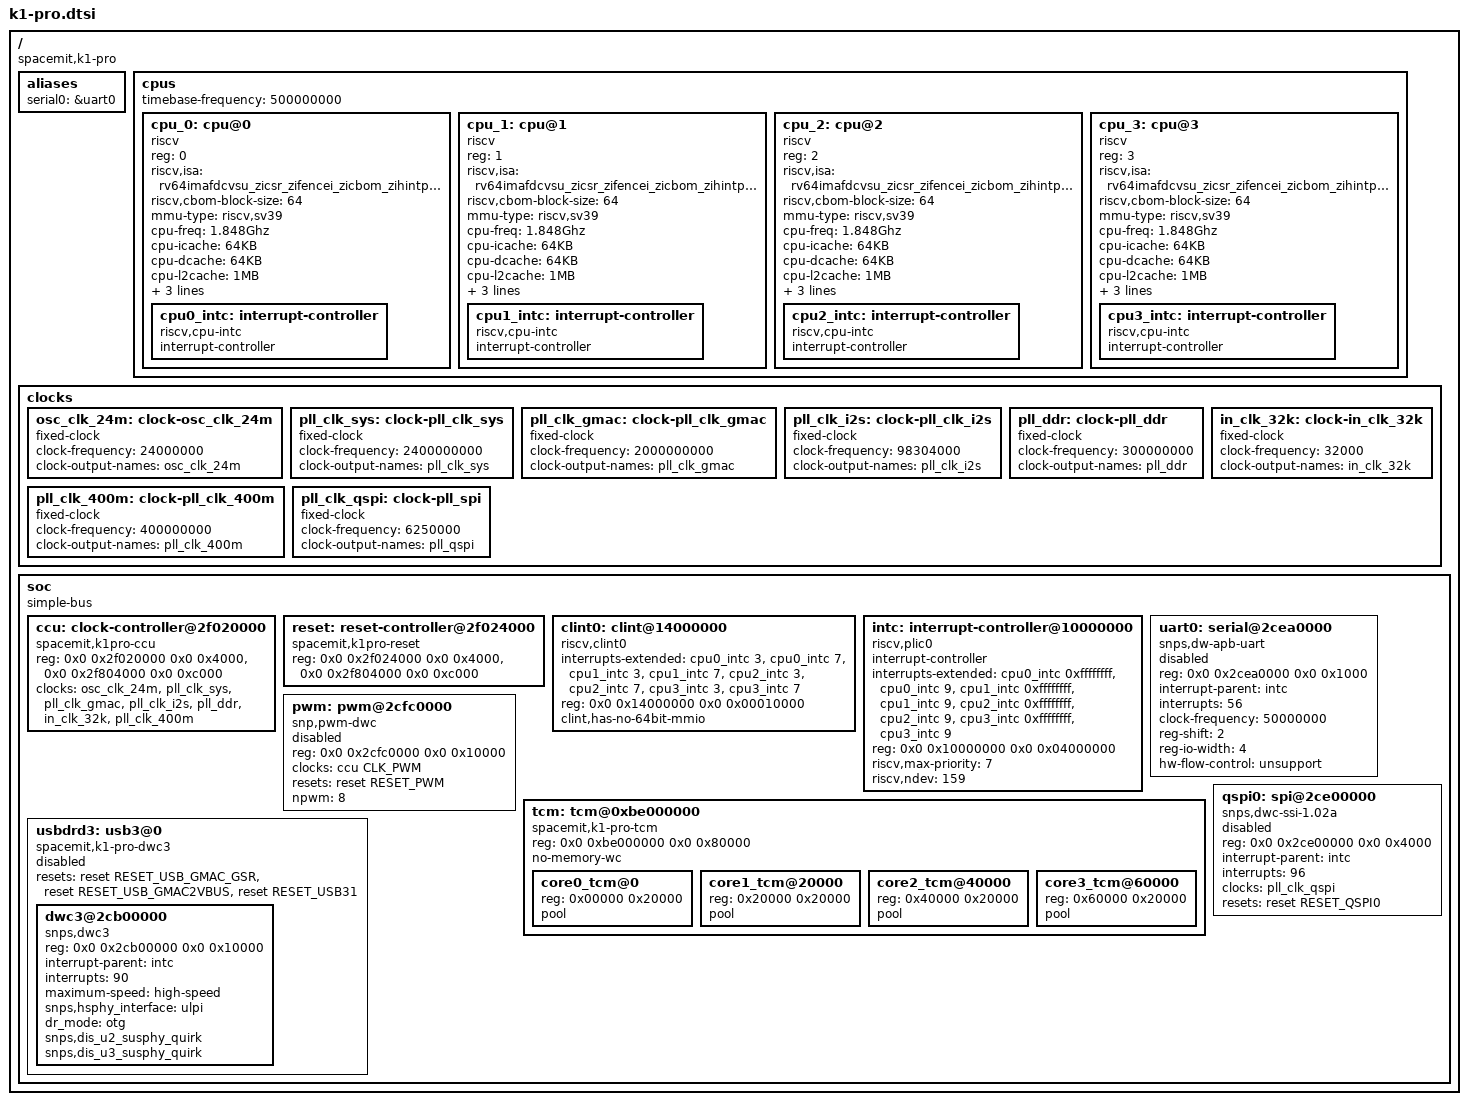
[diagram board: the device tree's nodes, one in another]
// SPDX-License-Identifier: (GPL-2.0 OR MIT)
/* Copyright (c) 2022 Spacemit, Inc */

/dts-v1/;

/dts-v1/;

#include <dt-bindings/clock/k1-pro-ccu-clock.h>
#include <dt-bindings/reset/k1-pro-reset.h>

/ {
	compatible = "spacemit,k1-pro", "riscv";
	#address-cells = <2>;
	#size-cells = <2>;

	aliases {
		serial0 = &uart0;
	};

	cpus: cpus {
		#address-cells = <1>;
		#size-cells = <0>;
		timebase-frequency = <500000000>;
		cpu_0: cpu@0 {
			device_type = "cpu";
			reg = <0>;
			status = "okay";
			compatible = "riscv";
			riscv,isa = "rv64imafdcvsu_zicsr_zifencei_zicbom_zihintpause_zba_zbb_zbc_zbs_svpbmt";
			riscv,cbom-block-size = <64>;
			mmu-type = "riscv,sv39";
			cpu-freq = "1.848Ghz";
			cpu-icache = "64KB";
			cpu-dcache = "64KB";
			cpu-l2cache = "1MB";
			cpu-tlb = "1024 4-ways";
			cpu-cacheline = "64Bytes";
			cpu-vector = "0.7.1";

			cpu0_intc: interrupt-controller {
				#interrupt-cells = <1>;
				compatible = "riscv,cpu-intc";
				interrupt-controller;
			};
		};
		cpu_1: cpu@1 {
			device_type = "cpu";
			reg = <1>;
			status = "okay";
			compatible = "riscv";
			riscv,isa = "rv64imafdcvsu_zicsr_zifencei_zicbom_zihintpause_zba_zbb_zbc_zbs_svpbmt";
			riscv,cbom-block-size = <64>;
			mmu-type = "riscv,sv39";
			cpu-freq = "1.848Ghz";
			cpu-icache = "64KB";
			cpu-dcache = "64KB";
			cpu-l2cache = "1MB";
			cpu-tlb = "1024 4-ways";
			cpu-cacheline = "64Bytes";
			cpu-vector = "0.7.1";

			cpu1_intc: interrupt-controller {
				#interrupt-cells = <1>;
				compatible = "riscv,cpu-intc";
				interrupt-controller;
			};
		};
		cpu_2: cpu@2 {
			device_type = "cpu";
			reg = <2>;
			status = "okay";
			compatible = "riscv";
			riscv,isa = "rv64imafdcvsu_zicsr_zifencei_zicbom_zihintpause_zba_zbb_zbc_zbs_svpbmt";
			riscv,cbom-block-size = <64>;
			mmu-type = "riscv,sv39";
			cpu-freq = "1.848Ghz";
			cpu-icache = "64KB";
			cpu-dcache = "64KB";
			cpu-l2cache = "1MB";
			cpu-tlb = "1024 4-ways";
			cpu-cacheline = "64Bytes";
			cpu-vector = "0.7.1";

			cpu2_intc: interrupt-controller {
				#interrupt-cells = <1>;
				compatible = "riscv,cpu-intc";
				interrupt-controller;
			};
		};
		cpu_3: cpu@3 {
			device_type = "cpu";
			reg = <3>;
			status = "okay";
			compatible = "riscv";
			riscv,isa = "rv64imafdcvsu_zicsr_zifencei_zicbom_zihintpause_zba_zbb_zbc_zbs_svpbmt";
			riscv,cbom-block-size = <64>;
			mmu-type = "riscv,sv39";
			cpu-freq = "1.848Ghz";
			cpu-icache = "64KB";
			cpu-dcache = "64KB";
			cpu-l2cache = "1MB";
			cpu-tlb = "1024 4-ways";
			cpu-cacheline = "64Bytes";
			cpu-vector = "0.7.1";

			cpu3_intc: interrupt-controller {
				#interrupt-cells = <1>;
				compatible = "riscv,cpu-intc";
				interrupt-controller;
			};
		};
	};

	clocks {
		#address-cells = <0x2>;
		#size-cells = <0x2>;
		ranges;

		osc_clk_24m: clock-osc_clk_24m {
			#clock-cells = <0>;
			compatible = "fixed-clock";
			clock-frequency = <24000000>;
			clock-output-names = "osc_clk_24m";
		};

		pll_clk_sys: clock-pll_clk_sys {
			#clock-cells = <0>;
			compatible = "fixed-clock";
			clock-frequency = <2400000000>;
			clock-output-names = "pll_clk_sys";
			};

		pll_clk_gmac: clock-pll_clk_gmac {
			#clock-cells = <0>;
			compatible = "fixed-clock";
			clock-frequency = <2000000000>;
			clock-output-names = "pll_clk_gmac";
		};
		pll_clk_i2s: clock-pll_clk_i2s {
			#clock-cells = <0>;
			compatible = "fixed-clock";
			clock-frequency = <98304000>;
			clock-output-names = "pll_clk_i2s";
		};

		pll_ddr: clock-pll_ddr {
			#clock-cells = <0>;
			compatible = "fixed-clock";
			clock-frequency = <300000000>;
			clock-output-names = "pll_ddr";
		};

		in_clk_32k: clock-in_clk_32k {
			#clock-cells = <0>;
			compatible = "fixed-clock";
			clock-frequency = <32000>;
			clock-output-names = "in_clk_32k";
		};

		pll_clk_400m: clock-pll_clk_400m {
			#clock-cells = <0>;
			compatible = "fixed-clock";
			clock-frequency = <400000000>;
			clock-output-names = "pll_clk_400m";
		};

               pll_clk_qspi: clock-pll_spi {
		       #clock-cells = <0>;
                       compatible = "fixed-clock";
                       clock-frequency = <6250000>;
                       clock-output-names = "pll_qspi";
               };
	};
	soc {
		compatible = "simple-bus";
		#address-cells = <2>;
		#size-cells = <2>;
		ranges;
		ccu:clock-controller@2f020000 {
		    #address-cells = <0x1>;
		    #size-cells = <0x1>;
			compatible = "spacemit,k1pro-ccu";
			reg = <0x0 0x2f020000 0x0 0x4000>, <0x0 0x2f804000 0x0 0xc000>;
			clocks = <&osc_clk_24m>, <&pll_clk_sys>, <&pll_clk_gmac>, <&pll_clk_i2s>, <&pll_ddr>, <&in_clk_32k>, <&pll_clk_400m>;
			clock-names = "osc_clk_24m", "pll_clk_sys", "pll_clk_gmac", "pll_clk_i2s", "pll_ddr", "in_clk_32k", "pll_clk_400m";
			#clock-cells = <1>;
			status = "okay";
		};

		reset: reset-controller@2f024000 {
		    #address-cells = <0x1>;
		    #size-cells = <0x1>;
			compatible = "spacemit,k1pro-reset";
			reg = <0x0 0x2f024000 0x0 0x4000>, <0x0 0x2f804000 0x0 0xc000>;
			#reset-cells = <1>;
			status = "okay";
		};

		clint0: clint@14000000 {
			compatible = "riscv,clint0";
			interrupts-extended = <
				&cpu0_intc  3 &cpu0_intc  7
				&cpu1_intc  3 &cpu1_intc  7
				&cpu2_intc  3 &cpu2_intc  7
				&cpu3_intc  3 &cpu3_intc  7
			>;
			reg = <0x0 0x14000000 0x0 0x00010000>;
			clint,has-no-64bit-mmio;
		};

		intc: interrupt-controller@10000000 {
			#interrupt-cells = <1>;
			compatible = "riscv,plic0";
			interrupt-controller;
			interrupts-extended = < 
				&cpu0_intc 0xffffffff &cpu0_intc 9
				&cpu1_intc 0xffffffff &cpu1_intc 9
				&cpu2_intc 0xffffffff &cpu2_intc 9
				&cpu3_intc 0xffffffff &cpu3_intc 9
			>;
			reg = <0x0 0x10000000 0x0 0x04000000>;
			reg-names = "control";
			riscv,max-priority = <7>;
			riscv,ndev = <159>;
		};

		/* Normal serial, log */
		uart0: serial@2cea0000 {
			compatible = "snps,dw-apb-uart";
			reg = <0x0 0x2cea0000 0x0 0x1000>;
			interrupt-parent = <&intc>;
			interrupts = <56>;
			clock-frequency = <50000000>;
			reg-shift = <2>;
			reg-io-width = <4>;
			hw-flow-control = "unsupport";
			status = "disabled";
		};

		pwm: pwm@2cfc0000 {
			compatible = "snp,pwm-dwc";
			reg = <0x0 0x2cfc0000 0x0 0x10000>;
			clocks = <&ccu CLK_PWM>;
			clock-names = "pwm-clk";
			resets = <&reset RESET_PWM>;
			#pwm-cells=<3>;
			npwm = <8>;
			status = "disabled";
		};

		tcm: tcm@0xbe000000 {
			compatible = "spacemit,k1-pro-tcm";
			reg = <0x0 0xbe000000 0x0 0x80000>;
			#address-cells = <1>;
			#size-cells = <1>;
			ranges = <0x0 0x0 0xbe000000 0x80000>;
			no-memory-wc;

			core0_tcm@0 {
				reg = <0x00000 0x20000>;
				pool;
			};
			core1_tcm@20000 {
				reg = <0x20000 0x20000>;
				pool;
			};
			core2_tcm@40000 {
				reg = <0x40000 0x20000>;
				pool;
			};
			core3_tcm@60000 {
				reg = <0x60000 0x20000>;
				pool;
			};
		};

		usbdrd3: usb3@0 {
			compatible = "spacemit,k1-pro-dwc3";
			#address-cells = <2>;
			#size-cells = <2>;
			resets = <&reset RESET_USB_GMAC_GSR>,
					 <&reset RESET_USB_GMAC2VBUS>,
					 <&reset RESET_USB31>;
			reset-names = "soft_rst", "bus_rst", "ctl_rst";
			ranges;
			status = "disabled";

			dwc3@2cb00000 {
				compatible = "snps,dwc3";
				reg = <0x0 0x2cb00000 0x0 0x10000>;
				interrupt-parent = <&intc>;
				interrupts = <90>;
				maximum-speed = "high-speed";
				snps,hsphy_interface = "ulpi";
				dr_mode = "otg";
				snps,dis_u2_susphy_quirk;
				snps,dis_u3_susphy_quirk;
			};
		};

		qspi0: spi@2ce00000 {
                       compatible = "snps,dwc-ssi-1.02a";
                       reg = <0x0 0x2ce00000 0x0 0x4000>;
                       interrupt-parent = <&intc>;
                       interrupts = <96>;
                       clocks = <&pll_clk_qspi>;
                       resets = <&reset RESET_QSPI0>;
                       #address-cells = <1>;
                       #size-cells = <0>;
                       status = "disabled";
               };



	};
};

